# SAMA7D65D4GN8 register map
Vendor: Microchip Technology; Series: SAMA7D6; File version: 0
Registers are 32-bit, read-write, reset 0x0 unless marked. A register's access mark holds for its fields unless they carry their own. Offsets are from the block's base; [hi:lo] are bit positions; lines under a group give offsets from that group; {n}, {i} and the like mark numbered series; 'fields as' and 'values as' point back to an identical list.

## GMAC0 (part 3 of 3) — Gigabit Ethernet MAC
Base 0xE1618000; register names take the prefix GMAC_
Same registers: GMAC1 0xE161C000
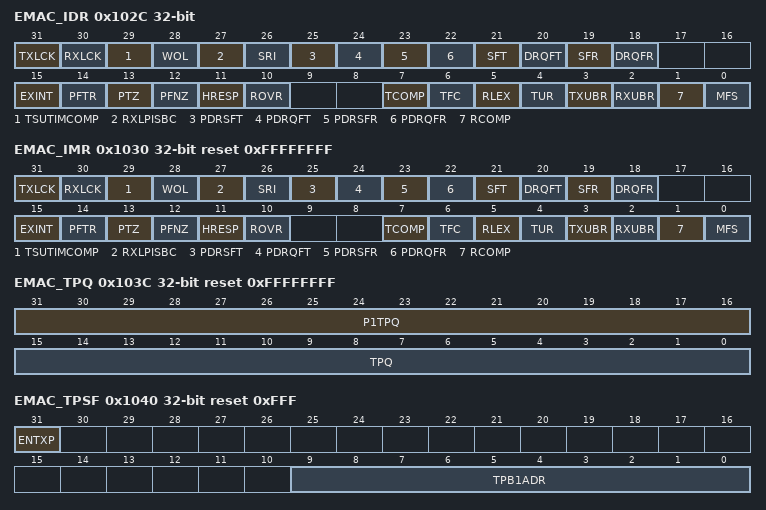
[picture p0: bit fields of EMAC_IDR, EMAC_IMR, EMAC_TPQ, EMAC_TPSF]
0x102C EMAC_IDR wo — Express MAC Interrupt Disable Register
  [31] TXLCK — Transmit Path Lockup Detected
  [30] RXLCK — Receive Path Lockup Detected
  [29] TSUTIMCOMP — TSU Timer Comparison
  [28] WOL — Wake On LAN
  [27] RXLPISBC — Enable RX LPI Indication
  [26] SRI — TSU Seconds Register Increment
  [25] PDRSFT — PDelay Response Frame Transmitted
  [24] PDRQFT — PDelay Request Frame Transmitted
  [23] PDRSFR — PDelay Response Frame Received
  [22] PDRQFR — PDelay Request Frame Received
  [21] SFT — PTP Sync Frame Transmitted
  [20] DRQFT — PTP Delay Request Frame Transmitted
  [19] SFR — PTP Sync Frame Received
  [18] DRQFR — PTP Delay Request Frame Received
  [15] EXINT — External Interrupt
  [14] PFTR — Pause Frame Transmitted
  [13] PTZ — Pause Time Zero
  [12] PFNZ — Pause Frame with Non-zero Pause Quantum Received
  [11] HRESP — System Bus Error
  [10] ROVR — Receive Overrun
  [7] TCOMP — Transmit Complete
  [6] TFC — Transmit Frame Corruption Due to System Bus Error
  [5] RLEX — Retry Limit Exceeded or Late Collision
  [4] TUR — Transmit Underrun
  [3] TXUBR — TX Used Bit Read
  [2] RXUBR — RX Used Bit Read
  [1] RCOMP — Receive Complete
  [0] MFS — Management Frame Sent
0x1030 EMAC_IMR reset 0xFFFFFFFF — Express MAC Interrupt Mask Register
  fields as EMAC_IDR
0x1038 EMAC_RPQ ro — Express MAC Receive Pause Quantum Register
  [15:0] RPQ — Received Pause Quantum
0x103C EMAC_TPQ reset 0xFFFFFFFF — Express MAC Transmit Pause Quantum Register
  [31:16] P1TPQ — Priority 1 Transmit Pause Quantum
  [15:0] TPQ — Transmit Pause Quantum
0x1040 EMAC_TPSF reset 0xFFF — Express MAC TX Partial Store and Forward Register
  [31] ENTXP — Enable TX Partial Store and Forward Operation
  [9:0] TPB1ADR — Transmit Partial Store and Forward Address
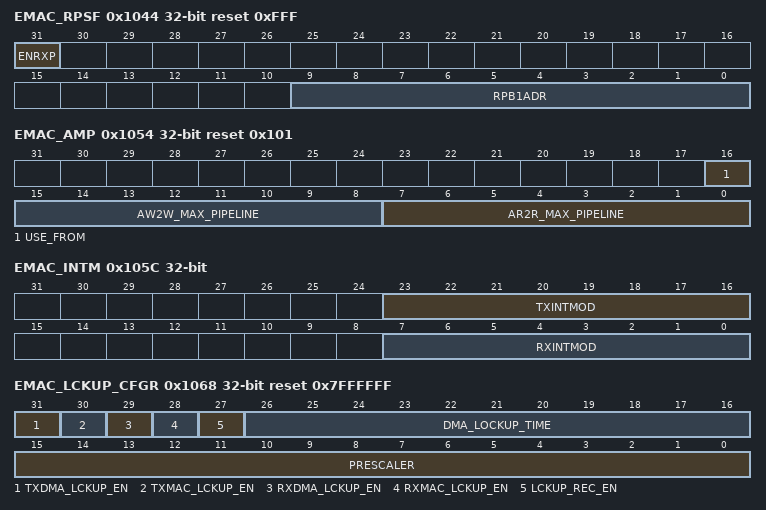
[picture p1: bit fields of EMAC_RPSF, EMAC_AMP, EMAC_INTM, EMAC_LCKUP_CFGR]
0x1044 EMAC_RPSF reset 0xFFF — Express MAC RX Partial Store and Forward Register
  [31] ENRXP — Enable RX Partial Store and Forward Operation
  [9:0] RPB1ADR — Receive Partial Store and Forward Address
0x1048 EMAC_RJFML reset 0x2800 — Express MAC RX Jumbo Frame Max Length Register
  [13:0] FML — Frame Max Length
0x1054 EMAC_AMP reset 0x101 — Express MAC System Bus Maximum Pipeline
  [16] USE_FROM — Address Write Bus to Write Data Bus Maximum Pipeline
    0=AW2W (Operates the AW2W_MAX_PIPELINE field between AW to W channel.); 1=AW2B (Operates the AW2W_MAX_PIPELINE field between AW to B channel.)
  [15:8] AW2W_MAX_PIPELINE — Address Write Bus to Write Data Bus Maximum Pipeline
  [7:0] AR2R_MAX_PIPELINE — Address Read Bus to Read Data Bus Maximum Pipeline
0x105C EMAC_INTM — Express MAC Interrupt Moderation Register
  [23:16] TXINTMOD — Transmit Interrupt Moderation
  [7:0] RXINTMOD — Receive Interrupt Moderation
0x1060 EMAC_SYSWT — Express MAC System Wake-Up Time Register
  [15:0] SYSWKUPTIME — System Wake-up Time
0x1068 EMAC_LCKUP_CFGR reset 0x7FFFFFF — Express MAC Lockup Detection and Recovery Configuration
  [31] TXDMA_LCKUP_EN — Transmit DMA Lockup Detector Enable
    0=Disables the monitor that detects lockups in the transmit DMA; 1=Enables the monitor that detects lockups in the transmit DMA
  [30] TXMAC_LCKUP_EN — Transmit MAC Lockup Detector Enable
    0=Disables the monitor that detects lockups in the transmit MAC; 1=Enables the monitor that detects lockups in the transmit MAC
  [29] RXDMA_LCKUP_EN — Receive DMA Lockup Detector Enable
    0=Disables the monitor that detects lockups in the receive DMA; 1=Enables the monitor that detects lockups in the receive DMA
  [28] RXMAC_LCKUP_EN — Receive MAC Lockup Detector Enable
    0=Disables the monitor that detects lockups in the receive MAC; 1=Enables the monitor that detects lockups in the receive MAC
  [27] LCKUP_REC_EN — Lockup RecoveryEnable
    0=No effect; 1=Forces the EMAC in Reset mode when a lockup.is detected on the transmit or receive data paths
  [26:16] DMA_LOCKUP_TIME — Timeout Value for Receive and Transmit DMA
  [15:0] PRESCALER — Prescaler Value for Timeout
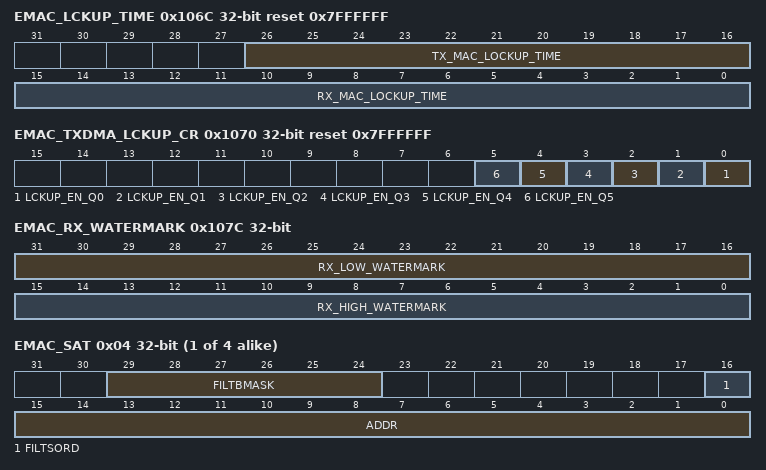
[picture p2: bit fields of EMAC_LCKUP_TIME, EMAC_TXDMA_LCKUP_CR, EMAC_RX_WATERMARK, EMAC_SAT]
0x106C EMAC_LCKUP_TIME reset 0x7FFFFFF — Express MAC Lockup Detection Time
  [26:16] TX_MAC_LOCKUP_TIME — Transmit MAC Lockup Detector Time
  [15:0] RX_MAC_LOCKUP_TIME — Receive MAC Lockup Detector Time
0x1070 EMAC_TXDMA_LCKUP_CR reset 0x7FFFFFF — Express MAC Transmit DMA Lockup Control Register
  [all] fields
    0=Disables the transmit DMA lockup timer for queue x. The number of outstanding packets are still counted but the actual timer does not run.; 1=Enables the transmit DMA lockup timer for queue x
  [n] LCKUP_EN_Q{n} (n=0..5) — Transmit DMA Lockup Detector Enable for Queue {n}
0x107C EMAC_RX_WATERMARK — Express MAC Receive Watermark Register
  [31:16] RX_LOW_WATERMARK — Receive Watermark Low Threshold
  [15:0] RX_HIGH_WATERMARK — Receive Watermark High Threshold
0x1080 EMAC_HRB — Express MAC Hash Register Bottom
  [31:0] ADDR — Hash Address
0x1084 EMAC_HRT — Express MAC Hash Register Top
  [31:0] ADDR — Hash Address
{0x1088+8i} GMAC_EMAC_SA[{i}] (i=0..3) group
  0x00 EMAC_SAB — Express MAC Specific Address Bottom Register
    [31:0] ADDR — Specific Address
  0x04 EMAC_SAT — Express MAC Specific Address Top Register
    [29:24] FILTBMASK — Filter Bytes Mask
      1=BIT1 (Controls whether the first byte has been received.); 2=BIT2 (Controls whether the second byte has been received.); 4=BIT3 (Controls whether the third byte has been received.); 8=BIT4 (Controls whether the fourth byte has been received.); 16=BIT5 (Controls whether the fifth byte has been received.); 32=BIT6 (Controls whether the sixth byte has been received)
    [16] FILTSORD — Filter Source or Destination MAC Address
      0=The filter is a destination address filter; 1=The filter is a source address filter
    [15:0] ADDR — Specific Address
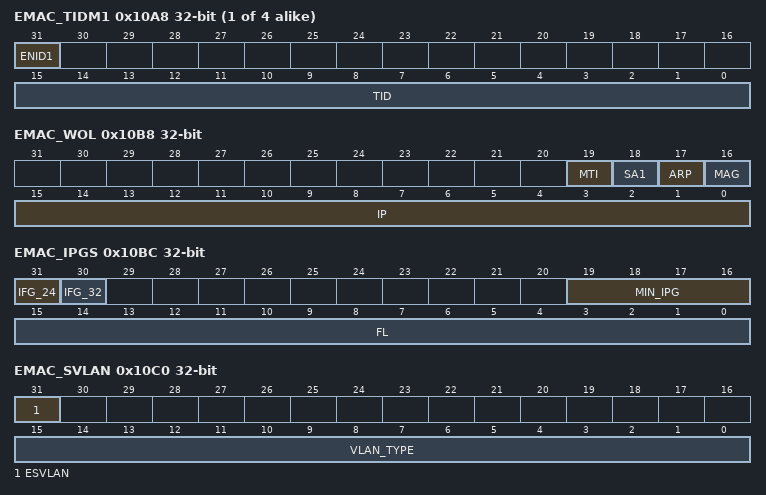
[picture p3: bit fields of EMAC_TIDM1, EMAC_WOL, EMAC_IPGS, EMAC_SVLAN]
{0x10A4+4i} EMAC_TIDM{i} (i=1..4) — Express MAC Type ID Match {i} Register
  [31] ENID{i} — Enable Copying of TID Matched Frames
    0=TID is not part of the comparison match; 1=TID is processed for the comparison match
  [15:0] TID — Type ID Match {i}
0x10B8 EMAC_WOL — Express MAC Wake on LAN Register
  [19] MTI — Multicast Hash Event Enable
  [18] SA1 — Specific Address Register 1 Event Enable
  [17] ARP — ARP Request Event Enable
  [16] MAG — Magic Packet Event Enable
  [15:0] IP — ARP Request IP Address
0x10BC EMAC_IPGS — Express MAC IPG Stretch Register
  [31] IFG_24 — Interframe Gap 24 bytes
    0=Defines a minimum interframe gap of 12 bytes when IFG_32=0; 1=Defines a minimum interframe gap of 24 bytes when MIN_IPG=0
  [30] IFG_32 — Interframe Gap 32 bytes
    0=Defines a minimum interframe gap of 12 bytes when IFG_24=0; 1=Defines a minimum interframe gap of 32 bytes when MIN_IPG=0
  [19:16] MIN_IPG — Minimum Interpacket Gap
  [15:0] FL — Frame Length
0x10C0 EMAC_SVLAN — Express MAC Stacked VLAN Register
  [31] ESVLAN — Enable Stacked VLAN Processing Mode
    0=Disable the stacked VLAN Processing mode; 1=Enable the stacked VLAN Processing mode
  [15:0] VLAN_TYPE — User Defined VLAN_TYPE Field
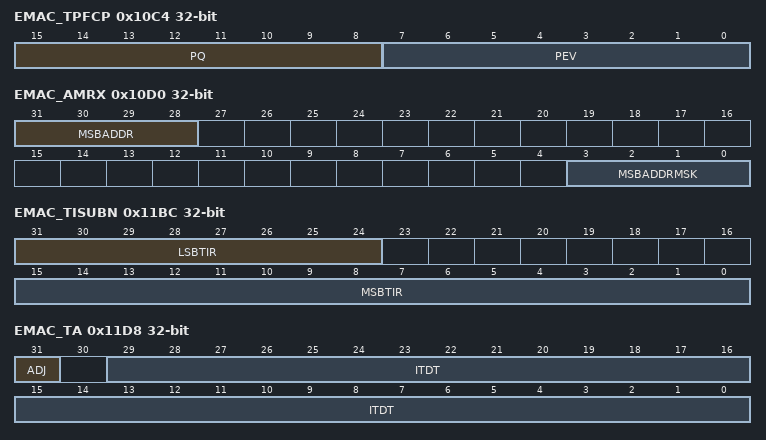
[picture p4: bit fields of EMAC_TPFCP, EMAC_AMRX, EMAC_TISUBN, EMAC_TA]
0x10C4 EMAC_TPFCP — Express MAC Transmit PFC Pause Register
  [15:8] PQ — Pause Quantum
  [7:0] PEV — Priority Enable Vector
0x10C8 EMAC_SAMB1 — Express MAC Specific Address 1 Mask Bottom Register
  [31:0] ADDR — Specific Address 1 Mask
0x10CC EMAC_SAMT1 — Express MAC Specific Address 1 Mask Top Register
  [15:0] ADDR — Specific Address 1 Mask
0x10D0 EMAC_AMRX — System Memory Address Mask for RX Data Buffer Accesses Register
  [31:28] MSBADDR — MSB of the Receive Data Buffer Address
  [3:0] MSBADDRMSK — Mask of the Receive Data Buffer Address
0x10D4 EMAC_RXUDAR — Express MAC PTP RX Unicast IP Destination Address Register
  [31:0] RXUDA — Receive Unicast Destination Address
0x10D8 EMAC_TXUDAR — Express MAC PTP TX Unicast IP Destination Address Register
  [31:0] TXUDA — Transmit Unicast Destination Address
0x10DC EMAC_NSC — Express MAC 1588 Timer Nanosecond Comparison Register
  [21:0] NANOSEC — 1588 Timer Nanosecond Comparison Value
0x10E0 EMAC_SCL — Express MAC 1588 Timer Second Comparison Low Register
  [31:0] SEC — 1588 Timer Second Comparison Value
0x10E4 EMAC_SCH — Express MAC 1588 Timer Second Comparison High Register
  [15:0] SEC — 1588 Timer Second Comparison Value
0x10E8 EMAC_EFTSH ro — Express MAC PTP Event Frame Transmitted Seconds High Register
  [15:0] RUD — Register Update
0x10EC EMAC_EFRSH ro — Express MAC PTP Event Frame Received Seconds High Register
  [15:0] RUD — Register Update
0x10F0 EMAC_PEFTSH ro — Express MAC PTP Peer Event Frame Transmitted Seconds High Register
  [15:0] RUD — Register Update
0x10F4 EMAC_PEFRSH ro — Express MAC PTP Peer Event Frame Received Seconds High Register
  [15:0] RUD — Register Update
0x1100 EMAC_OTLO ro — Express MAC Octets Transmitted Low Register
  [31:0] TXO — Transmitted Octets
0x1104 EMAC_OTHI ro — Express MAC Octets Transmitted High Register
  [15:0] TXO — Transmitted Octets
0x1108 EMAC_FT ro — Express MAC Frames Transmitted Register
  [31:0] FTX — Frames Transmitted without Error
0x110C EMAC_BCFT ro — Express MAC Broadcast Frames Transmitted Register
  [31:0] BFTX — Broadcast Frames Transmitted without Error
0x1110 EMAC_MFT ro — Express MAC Multicast Frames Transmitted Register
  [31:0] MFTX — Multicast Frames Transmitted without Error
0x1114 EMAC_PFT ro — Express MAC Pause Frames Transmitted Register
  [15:0] PFTX — Pause Frames Transmitted Register
0x1118 EMAC_BFT64 ro — Express MAC 64 Byte Frames Transmitted Register
  [31:0] NFTX — 64 Byte Frames Transmitted without Error
0x111C EMAC_TBFT127 ro — Express MAC 65 to 127 Byte Frames Transmitted Register
  [31:0] NFTX — 65 to 127 Byte Frames Transmitted without Error
0x1120 EMAC_TBFT255 ro — Express MAC 128 to 255 Byte Frames Transmitted Register
  [31:0] NFTX — 128 to 255 Byte Frames Transmitted without Error
0x1124 EMAC_TBFT511 ro — Express MAC 256 to 511 Byte Frames Transmitted Register
  [31:0] NFTX — 256 to 511 Byte Frames Transmitted without Error
0x1128 EMAC_TBFT1023 ro — Express MAC 512 to 1023 Byte Frames Transmitted Register
  [31:0] NFTX — 512 to 1023 Byte Frames Transmitted without Error
0x112C EMAC_TBFT1518 ro — Express MAC 1024 to 1518 Byte Frames Transmitted Register
  [31:0] NFTX — 1024 to 1518 Byte Frames Transmitted without Error
0x1130 EMAC_GTBFT1518 ro — Express MAC Greater Than 1518 Byte Frames Transmitted Register
  [31:0] NFTX — Greater than 1518 Byte Frames Transmitted without Error
0x1134 EMAC_TUR ro — Express MAC Transmit Underruns Register
  [9:0] TXUNR — Transmit Underruns
0x1138 EMAC_SCF ro — Express MAC Single Collision Frames Register
  [17:0] SCOL — Single Collision
0x113C EMAC_MCF ro — Express MAC Multiple Collision Frames Register
  [17:0] MCOL — Multiple Collision
0x1140 EMAC_EC ro — Express MAC Excessive Collisions Register
  [9:0] XCOL — Excessive Collisions
0x1144 EMAC_LC ro — Express MAC Late Collisions Register
  [9:0] LCOL — Late Collisions
0x1148 EMAC_DTF ro — Express MAC Deferred Transmission Frames Register
  [17:0] DEFT — Deferred Transmission
0x114C EMAC_CSE ro — Express MAC Carrier Sense Errors Register
  [9:0] CSR — Carrier Sense Error
0x1150 EMAC_ORLO ro — Express MAC Octets Received Low Received Register
  [31:0] RXO — Received Octets
0x1154 EMAC_ORHI ro — Express MAC Octets Received High Received Register
  [15:0] RXO — Received Octets
0x1158 EMAC_FR ro — Express MAC Frames Received Register
  [31:0] FRX — Frames Received without Error
0x115C EMAC_BCFR ro — Express MAC Broadcast Frames Received Register
  [31:0] BFRX — Broadcast Frames Received without Error
0x1160 EMAC_MFR ro — Express MAC Multicast Frames Received Register
  [31:0] MFRX — Multicast Frames Received without Error
0x1164 EMAC_PFR ro — Express MAC Pause Frames Received Register
  [15:0] PFRX — Pause Frames Received Register
0x1168 EMAC_BFR64 ro — Express MAC 64 Byte Frames Received Register
  [31:0] NFRX — 64 Byte Frames Received without Error
0x116C EMAC_TBFR127 ro — Express MAC 65 to 127 Byte Frames Received Register
  [31:0] NFRX — 65 to 127 Byte Frames Received without Error
0x1170 EMAC_TBFR255 ro — Express MAC 128 to 255 Byte Frames Received Register
  [31:0] NFRX — 128 to 255 Byte Frames Received without Error
0x1174 EMAC_TBFR511 ro — Express MAC 256 to 511 Byte Frames Received Register
  [31:0] NFRX — 256 to 511 Byte Frames Received without Error
0x1178 EMAC_TBFR1023 ro — Express MAC 512 to 1023 Byte Frames Received Register
  [31:0] NFRX — 512 to 1023 Byte Frames Received without Error
0x117C EMAC_TBFR1518 ro — Express MAC 1024 to 1518 Byte Frames Received Register
  [31:0] NFRX — 1024 to 1518 Byte Frames Received without Error
0x1180 EMAC_TMXBFR ro — Express MAC 1519 to Maximum Byte Frames Received Register
  [31:0] NFRX — 1519 to Maximum Byte Frames Received without Error
0x1184 EMAC_UFR ro — Express MAC Undersize Frames Received Register
  [9:0] UFRX — Undersize Frames Received
0x1188 EMAC_OFR ro — Express MAC Oversize Frames Received Register
  [9:0] OFRX — Oversized Frames Received
0x118C EMAC_JR ro — Express MAC Jabbers Received Register
  [9:0] JRX — Jabbers Received
0x1190 EMAC_FCSE ro — Express MAC Frame Check Sequence Errors Register
  [9:0] FCKR — Frame Check Sequence Errors
0x1194 EMAC_LFFE ro — Express MAC Length Field Frame Errors Register
  [9:0] LFER — Length Field Frame Errors
0x1198 EMAC_RSE ro — Express MAC Receive Symbol Errors Register
  [9:0] RXSE — Receive Symbol Errors
0x119C EMAC_AE ro — Express MAC Alignment Errors Register
  [9:0] AER — Alignment Errors
0x11A0 EMAC_RRE ro — Express MAC Receive Resource Errors Register
  [17:0] RXRER — Receive Resource Errors
0x11A4 EMAC_ROE ro — Express MAC Receive Overrun Register
  [9:0] RXOVR — Receive Overruns
0x11A8 EMAC_IHCE ro — Express MAC IP Header Checksum Errors Register
  [7:0] HCKER — IP Header Checksum Errors
0x11AC EMAC_TCE ro — Express MAC TCP Checksum Errors Register
  [7:0] TCKER — TCP Checksum Errors
0x11B0 EMAC_UCE ro — Express MAC UDP Checksum Errors Register
  [7:0] UCKER — UDP Checksum Errors
0x11B4 EMAC_FLRXPCR ro — Express MAC Flushed Received Packets Counter Register
  [15:0] COUNT — Flushed Received Packets Count (cleared on read)
0x11BC EMAC_TISUBN — Express MAC 1588 Timer Increment Sub-nanoseconds Register
  [31:24] LSBTIR — Lower Significant Bits of Timer Increment Register
  [15:0] MSBTIR — Most Significant Bits of Timer Increment Register
0x11C0 EMAC_TSH — Express MAC1588 Timer Seconds High Register
  [15:0] TCS — Timer Count in Seconds
0x11D0 EMAC_TSL — Express MAC1588 Timer Seconds Low Register
  [31:0] TCS — Timer Count in Seconds
0x11D4 EMAC_TN — Express MAC1588 Timer Nanoseconds Register
  [29:0] TNS — Timer Count in Nanoseconds
0x11D8 EMAC_TA wo — Express MAC1588 Timer Adjust Register
  [31] ADJ — Adjust 1588 Timer
  [29:0] ITDT — Increment/Decrement
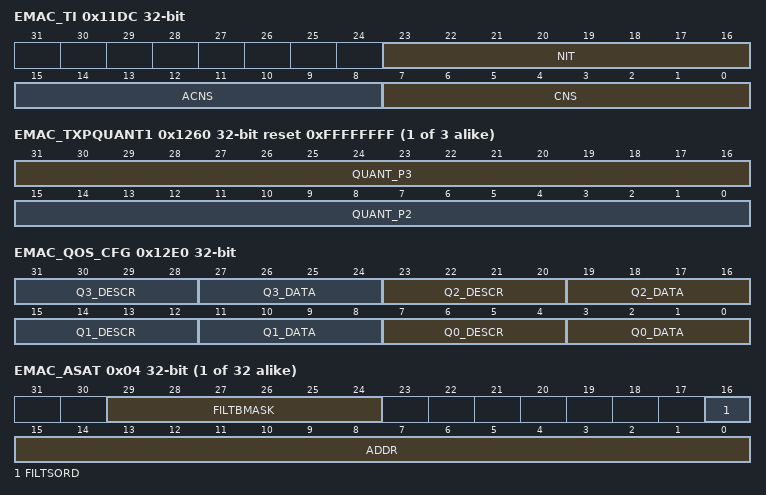
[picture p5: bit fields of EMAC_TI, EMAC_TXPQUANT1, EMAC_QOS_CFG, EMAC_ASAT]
0x11DC EMAC_TI — Express MAC1588 Timer Increment Register
  [23:16] NIT — Number of Increments
  [15:8] ACNS — Alternative Count Nanoseconds
  [7:0] CNS — Count Nanoseconds
0x11E0 EMAC_EFTSL ro — Express MAC PTP Event Frame Transmitted Seconds Low Register
  [31:0] RUD — Register Update
0x11E4 EMAC_EFTN ro — Express MAC PTP Event Frame Transmitted Nanoseconds Register
  [29:0] RUD — Register Update
0x11E8 EMAC_EFRSL ro — Express MAC PTP Event Frame Received Seconds Low Register
  [31:0] RUD — Register Update
0x11EC EMAC_EFRN ro — Express MAC PTP Event Frame Received Nanoseconds Register
  [29:0] RUD — Register Update
0x11F0 EMAC_PEFTSL ro — Express MAC PTP Peer Event Frame Transmitted Seconds Low Register
  [31:0] RUD — Register Update
0x11F4 EMAC_PEFTN ro — Express MAC PTP Peer Event Frame Transmitted Nanoseconds Register
  [29:0] RUD — Register Update
0x11F8 EMAC_PEFRSL ro — Express MAC PTP Peer Event Frame Received Seconds Low Register
  [31:0] RUD — Register Update
0x11FC EMAC_PEFRN ro — Express MAC PTP Peer Event Frame Received Nanoseconds Register
  [29:0] RUD — Register Update
{0x125C+4i} EMAC_TXPQUANT{i} reset 0xFFFFFFFF (i=1..3) — Express MAC Transmit Pause Quantum {i} Register
  [31:16] QUANT_P{2i+1} — Priority {2i+1} Transmit Pause Quantum
  [15:0] QUANT_P{2i} — Priority {2i} Transmit Pause Quantum
0x1270 EMAC_RXLPI ro — Express MAC Received LPI Transitions
  [15:0] COUNT — Count of Received LPI transitions (cleared on read)
0x1274 EMAC_RXLPITIME ro — Express MAC Received LPI Time
  [23:0] LPITIME — Time in LPI (cleared on read)
0x1278 EMAC_TXLPI ro — Express MAC Transmit LPI Transitions
  [15:0] COUNT — Count of LPI transitions (cleared on read)
0x127C EMAC_TXLPITIME ro — Express MAC Transmit LPI Time
  [23:0] LPITIME — Time in LPI (cleared on read)
0x12E0 EMAC_QOS_CFG — Express MAC System Bus QoS Configuration Register
  [8n+7:8n+4] Q{n}_DESCR (n=0..3) — System Bus QoS Attributes for Queue {n} Descriptor Access
  [8n+3:8n] Q{n}_DATA (n=0..3) — System Bus QoS Attributes for Queue {n} Data Access
{0x1300+8i} GMAC_EMAC_ASA[{i}] (i=0..31) group
  0x00 EMAC_ASAB — Express MAC Additional Specific Address Bottom Register
    [31:0] ADDR — Specific Address
  0x04 EMAC_ASAT — Express MAC Additional Specific Address Top Register
    fields as GMAC_EMAC_SA[0].EMAC_SAT
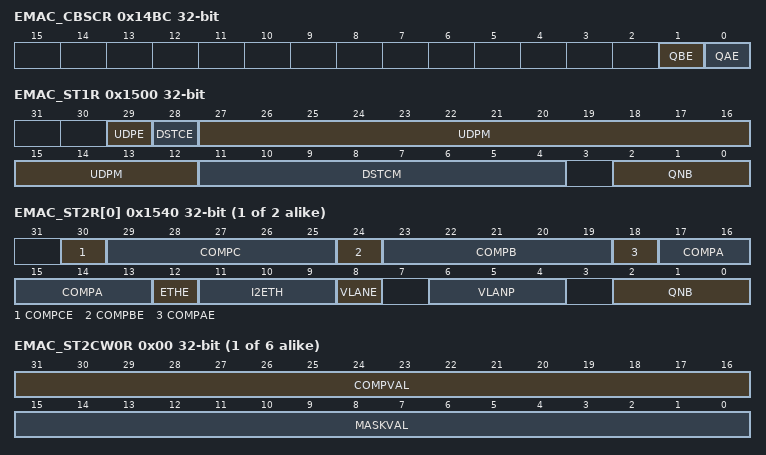
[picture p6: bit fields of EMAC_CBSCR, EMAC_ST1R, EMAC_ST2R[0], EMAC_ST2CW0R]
0x14BC EMAC_CBSCR — Express MAC Credit-Based Shaping Control Register
  [1] QBE — Queue B CBS Enable
    0=Credit-based shaping on the highest priority queue (queue B) is disabled; 1=Credit-based shaping on the highest priority queue (queue B) is enabled
  [0] QAE — Queue A CBS Enable
    0=Credit-based shaping on the second highest priority queue (queue A) is disabled; 1=Credit-based shaping on the second highest priority queue (queue A) is enabled
0x14C0 EMAC_CBSISQA — Express MAC Credit-Based Shaping IdleSlope Register for Queue A
  [31:0] IS — IdleSlope
0x14C4 EMAC_CBSISQB — Express MAC Credit-Based Shaping IdleSlope Register for Queue B
  [31:0] IS — IdleSlope
0x14C8 EMAC_TQUBA — Express MAC 32 MSB Transmit Buffer Descriptor Queue Base Address Register
  [31:0] TQUBA — Transmit Queue Upper Buffer Address
0x14CC EMAC_TXBDCTRL — Express MAC Transmit Buffer Data Control Register
  [5:4] TSMODE — Transmit Descriptor Timestamp Insertion Mode
    0=DISABLE (Timestamp insertion disable.); 1=PTPEVENT (Timestamp inserted for PTP Event Frames only.); 2=PTPALL (Timestamp inserted for All PTP Frames only.); 3=ALL (Timestamp inserted for All Frames.)
0x14D0 EMAC_RXBDCTRL — Express MAC Receive Buffer Data Control Register
  [5:4] TSMODE — Receive Descriptor Timestamp Insertion Mode
    values as EMAC_TXBDCTRL.TSMODE
0x14D4 EMAC_RQUBA — Express MAC 32 MSB Receive Buffer Descriptor Queue Base Address Register
  [31:0] RQUBA — Receive Queue Upper Buffer Address
0x1500 EMAC_ST1R — Express MAC Screening Type 1 Register
  [29] UDPE — UDP Port Match Enable
  [28] DSTCE — Differentiated Services or Traffic Class Match Enable
  [27:12] UDPM — UDP Port Match
  [11:4] DSTCM — Differentiated Services or Traffic Class Match
  [2:0] QNB — Queue Number (0-5)
{0x1540+4i} EMAC_ST2R[{i}] (i=0..1) — Express MAC Screening Type 2 Register (index = 0)
  [30] COMPCE — Compare C Enable
    0=Comparison via the register designated by index COMPC is disabled; 1=Comparison via the register designated by index COMPC is enabled
  [29:25] COMPC — Index of Screening Type 2 Compare Word 0/Word 1 register
  [24] COMPBE — Compare B Enable
    0=Comparison via the register designated by index COMPB is disabled; 1=Comparison via the register designated by index COMPB is enabled
  [23:19] COMPB — Index of Screening Type 2 Compare Word 0/Word 1 register
  [18] COMPAE — Compare A Enable
    0=Comparison via the register designated by index COMPA is disabled; 1=Comparison via the register designated by index COMPA is enabled
  [17:13] COMPA — Index of Screening Type 2 Compare Word 0/Word 1 register
  [12] ETHE — EtherType Enable
    0=EtherType match with bits 15:0 in the register designated by the value of I2ETH is disabled; 1=EtherType match with bits 15:0 in the register designated by the value of I2ETH is enabled
  [11:9] I2ETH — Index of Screening Type 2 EtherType register
  [8] VLANE — VLAN Enable
    0=VLAN match is disabled; 1=VLAN match is enabled
  [6:4] VLANP — VLAN Priority
  [2:0] QNB — Queue Number (0-5)
0x1580 EMAC_TSCTL — Express MACTransmit Schedule Control Register
  [1:0] TXSQ — Transmit Schedule for Q0
    0=FP (Fixed Priority); 1=CBS (CBS Enabled only valid if CBS capability selected); 2=DWRR (DWRR enabled); 3=ETS (ETS enabled)
0x1590 EMAC_TQBWRL — Express MAC Transmit Queue Bandwidth Rate Limit Register
  [7:0] ALLOCQ0 — DWRR Weighting or ETS Bandwidth Allocation for EMAC
0x15A0 EMAC_TQSA — Express MAC Transmit Queue Segment Allocation Register
  [2:0] SEGALLOCQ0 — Segment Allocation for EMAC
{0x1700+8i} GMAC_EMAC_ST2CW[{i}] (i=0..5) group
  0x00 EMAC_ST2CW0R — Express MAC Screening Type 2 Compare Word 0 Register
    [31:16] COMPVAL — Compare Value
    [15:0] MASKVAL — Mask Value
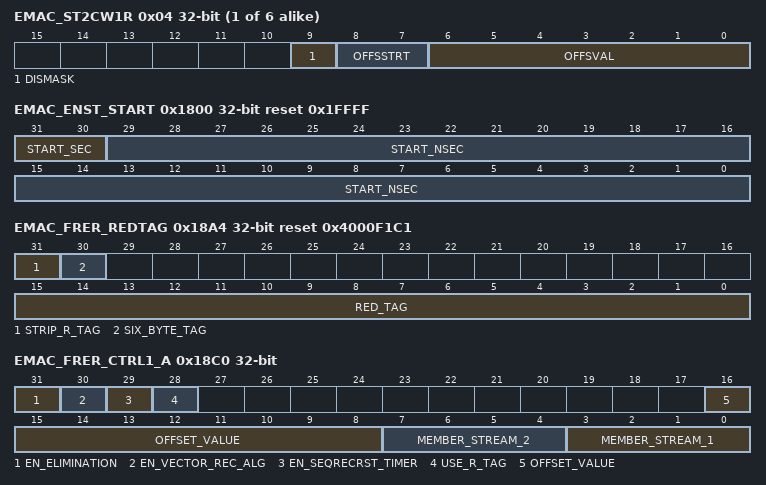
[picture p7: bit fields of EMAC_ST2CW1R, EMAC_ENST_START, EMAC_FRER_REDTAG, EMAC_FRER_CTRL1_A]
  0x04 EMAC_ST2CW1R — Express MAC Screening Type 2 Compare Word 1 Register
    [9] DISMASK — Disable Mask
      0=GMAC_EMAC_ST2CW0R contains a 2-byte compare value with a 2-byte mask value; 1=GMAC_EMAC_ST2CW0R contains a 4-byte compare value
    [8:7] OFFSSTRT — Ethernet Frame Offset Start
      0=FRAMESTART (Offset from the start of the frame); 1=ETHERTYPE (Offset from the byte after the EtherType field); 2=IP (Offset from the byte after the IP header field); 3=TCP_UDP (Offset from the byte after the TCP/UDP header field)
    [6:0] OFFSVAL — Offset Value in Bytes
0x1800 EMAC_ENST_START reset 0x1FFFF — Express MAC ENST Start Time Queue Register
  [31:30] START_SEC — Seconds for Start Time
  [29:0] START_NSEC — Nanoseconds for Start Time
0x1820 EMAC_ENST_ON reset 0x1FFFF — Express MAC ENST On Time Queue Register
  [16:0] ON_TIME — Time for which the Queue is to be Open
0x1840 EMAC_ENST_OFF — Express MAC ENST Off Time Queue Register
  [16:0] OFF_TIME — Time for which the Queue is to be Blocked
0x1880 EMAC_ENST_CR — Express MAC ENST Control Register
  [0] EN_Q0 — Enhanced Scheduled Traffic Enable for EMAC
    0=Disables the enhanced scheduled traffic for EMAC; 1=Enables the enhanced scheduled traffic for EMAC. EMAC has only 1 queue and ENST is enabled by writing EN_Q0.
0x18A0 EMAC_FRER_TIMEOUT — Express MAC Frame Elimination Timeout Register
  [15:0] TIMEOUT — Sequence Recovery Timer Restart Period for Credit Based Streams
0x18A4 EMAC_FRER_REDTAG reset 0x4000F1C1 — Express MAC Frame Elimination Redundancy Tag Register
  [31] STRIP_R_TAG — Stripping Redundancy Tag Enable
    0=Disables the stripping function. When the statistics counters need to reflect the actual number of octets received, then the stripping functionality must be disabled.; 1=Enables the stripping function, the receive octet counters reflect post deletion frame size so the frame elimination functionality is transparent to higher level management
  [30] SIX_BYTE_TAG — Six-byte Tag Enable
    0=Defines a four-byte tag as per 802.1CB standard revision 2.4 and earlier; 1=Enables the six-byte tag as per 802.1CB standard revision 2.4 and later
  [15:0] RED_TAG — Redundancy Tag (R-TAG)
0x18C0 EMAC_FRER_CTRL1_A — Express MAC Frame Elimination Control1 A Register
  [31] EN_ELIMINATION — 802.1CB Elimination of Received Frames Enable
    0=Disables the elimination of received frames; 1=Enables the elimination of received frames
  [30] EN_VECTOR_REC_ALG — 802.1CB Vector Recovery Algorithm Enable
    0=Enables the match recovery algorithm; 1=Enables the vector recovery algorithm
  [29] EN_SEQRECRST_TIMER — 802.1CB Sequence Recovery Reset Timer Enable
    0=Disables the sequence recovery reset timer; 1=Enables the sequence recovery reset timer
  [28] USE_R_TAG — Redundancy Tag Enable
    0=Identifies bottom of sequence number with OFFSET_VALUE; 1=Identifies sequence number with redundancy tag
  [16:8] OFFSET_VALUE — Offset in Bytes from Start Packet Delimiter to MSB for 802.1CB Sequence Number
  [7:4] MEMBER_STREAM_2 — Pointer to Screener Type 2 Register
  [3:0] MEMBER_STREAM_1 — Pointer to Screener Type 2 Register
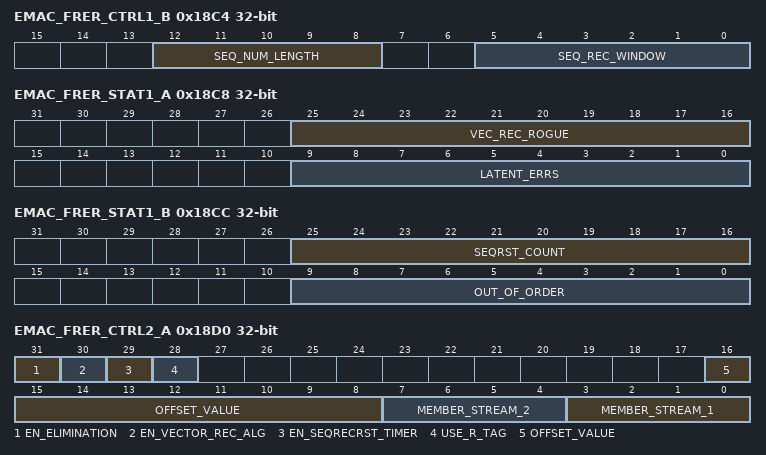
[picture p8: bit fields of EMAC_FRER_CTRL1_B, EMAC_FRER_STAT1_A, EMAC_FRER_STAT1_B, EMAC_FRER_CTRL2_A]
0x18C4 EMAC_FRER_CTRL1_B — Express MAC Frame Elimination Control1 B Register
  [12:8] SEQ_NUM_LENGTH — Number of Significants bits of the 802.1CB Sequence Number
  [5:0] SEQ_REC_WINDOW — Vector Recovery Window
0x18C8 EMAC_FRER_STAT1_A — Express MAC Frame Elimination Statistics1 A Register
  [25:16] VEC_REC_ROGUE — Number of Dropped Frames (Clear on read)
  [9:0] LATENT_ERRS — Number of Sequence Numbers Seen Without a Duplicate (Clear on read)
0x18CC EMAC_FRER_STAT1_B — Express MAC Frame Elimination Statistics1 B Register
  [25:16] SEQRST_COUNT — Number of Times the Sequence Recovery Reset Timer Decrements to Zero (Clear on read)
  [9:0] OUT_OF_ORDER — Out of Order Sequence Numbers Received (Clear on read)
0x18D0 EMAC_FRER_CTRL2_A — Express MAC Frame Elimination Control2 A Register
  fields as EMAC_FRER_CTRL1_A
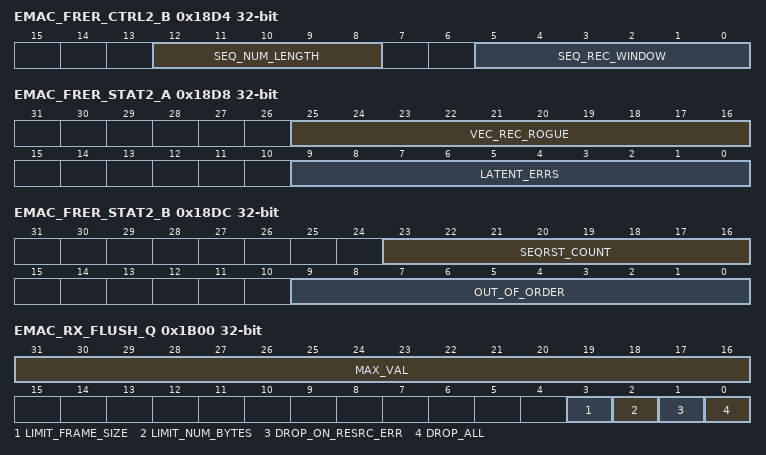
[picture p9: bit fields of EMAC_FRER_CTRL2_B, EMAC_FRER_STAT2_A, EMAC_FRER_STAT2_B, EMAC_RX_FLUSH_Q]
0x18D4 EMAC_FRER_CTRL2_B — Express MAC Frame Elimination Control2 B Register
  fields as EMAC_FRER_CTRL1_B
0x18D8 EMAC_FRER_STAT2_A — Express MAC Frame Elimination Statistics2 A Register
  fields as EMAC_FRER_STAT1_A
0x18DC EMAC_FRER_STAT2_B — Express MAC Frame Elimination Statistics2 B Register
  [23:16] SEQRST_COUNT — Number of Times the Sequence Recovery Reset Timer Decrements to Zero (Clear on read)
  [9:0] OUT_OF_ORDER — Out of Order Sequence Numbers Received (Clear on read)
0x1B00 EMAC_RX_FLUSH_Q — Express MAC Receive Queue Flush Register
  [31:16] MAX_VAL — Maximum Value for the Received Frame Size or Number of 128-Byte Chunk
  [3] LIMIT_FRAME_SIZE — Maximum Frame-length Received
    0=DISABLED (No effect.); 1=ENABLED (When set, MAX_VAL indicates the maximum frame-length in bytes that may be received. Frames exceeding this length will be dropped. This traffic policing function is relevant to the 802.1Qci standard which specifies stream filtering based on a maximum service data unit (SDU) size.)
  [2] LIMIT_NUM_BYTES — Limitation of the Number of 128-Byte Chunk of Data Stored in the Memory of this Queue
    0=DISABLED (No effect.); 1=ENABLED (Limits the number of 128 byte chunks of data received for this queue and already stored in the memory of the queue awaiting DMA memory writes to the value defined in the field MAX_VAL.)
  [1] DROP_ON_RESRC_ERR — Drop on Resource Error
    0=DISABLED (No effect.); 1=ENABLED (If a free DMA descriptor for this queue cannot be obtained (also referred to as lack of descriptor resource and occurs when the software either cannot free up descriptors quickly enough to meet the receive traffic rate or has deliberately decided not to free any descriptors), all new frames received on this queue will be automatically discarded.)
  [0] DROP_ALL — Drop All Frames
    0=DISABLED (No effect.); 1=ENABLED (Drops all frames of this queue.)
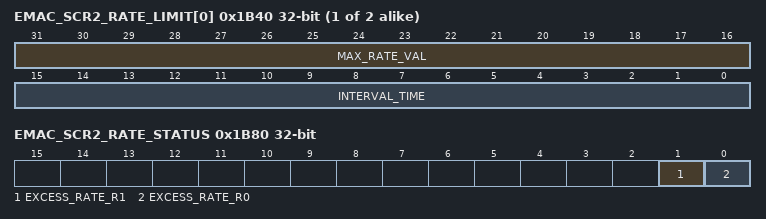
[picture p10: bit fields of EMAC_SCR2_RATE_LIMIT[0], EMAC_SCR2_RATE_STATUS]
{0x1B40+4i} EMAC_SCR2_RATE_LIMIT[{i}] (i=0..1) — Express MAC Screening 2 Rate Limit Register x
  [31:16] MAX_RATE_VAL — Maximum Rate Value for the Interval Time
  [15:0] INTERVAL_TIME — Interval Time for Maximum Rate Checking
0x1B80 EMAC_SCR2_RATE_STATUS ro — Express MAC Screening 2 Rate Status Register
  [1] EXCESS_RATE_R1 — Excessive Screener Rate Register
    0=No excessive rate in screener since the last read of GMAC_EMAC_SCR2_RATE_STATUS; 1=A screener rate limiting mechanism has been triggered since the last read of GMAC_EMAC_SCR2_RATE_STATUS
  [0] EXCESS_RATE_R0 — Excessive Screener Rate Register
    values as EXCESS_RATE_R1
